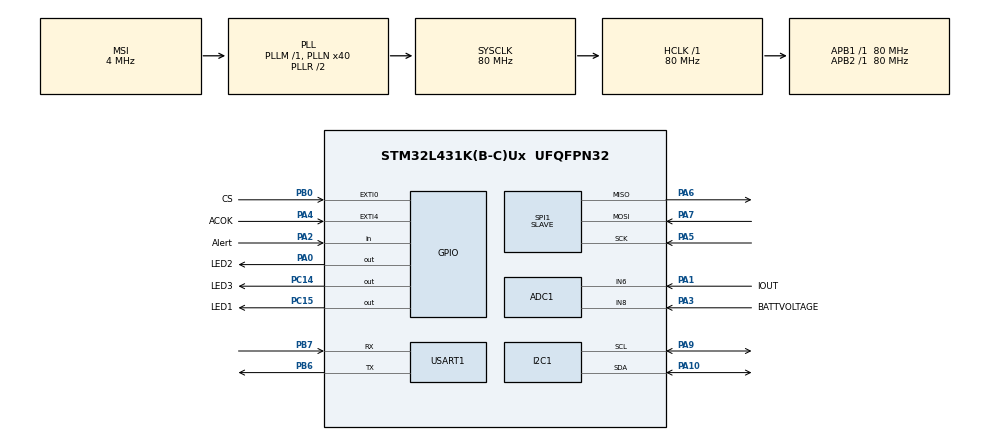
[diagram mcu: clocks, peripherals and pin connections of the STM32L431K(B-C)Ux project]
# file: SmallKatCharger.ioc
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ADC1.Channel-0\#ChannelRegularConversion=ADC_CHANNEL_6
ADC1.DMAContinuousRequests=DISABLE
ADC1.NbrOfConversionFlag=1
ADC1.OffsetNumber-0\#ChannelRegularConversion=ADC_OFFSET_NONE
ADC1.Rank-0\#ChannelRegularConversion=1
ADC1.SamplingTime-0\#ChannelRegularConversion=ADC_SAMPLETIME_2CYCLES_5
ADC1.master=1
Dma.ADC1.2.Direction=DMA_PERIPH_TO_MEMORY
Dma.ADC1.2.Instance=DMA1_Channel1
Dma.ADC1.2.MemDataAlignment=DMA_MDATAALIGN_HALFWORD
Dma.ADC1.2.MemInc=DMA_MINC_ENABLE
Dma.ADC1.2.Mode=DMA_NORMAL
Dma.ADC1.2.PeriphDataAlignment=DMA_PDATAALIGN_HALFWORD
Dma.ADC1.2.PeriphInc=DMA_PINC_DISABLE
Dma.ADC1.2.Priority=DMA_PRIORITY_LOW
Dma.Request0=SPI1_RX
Dma.Request1=SPI1_TX
Dma.Request2=ADC1
Dma.SPI1_RX.0.Direction=DMA_PERIPH_TO_MEMORY
Dma.SPI1_RX.0.Instance=DMA1_Channel2
Dma.SPI1_RX.0.MemDataAlignment=DMA_MDATAALIGN_HALFWORD
Dma.SPI1_RX.0.MemInc=DMA_MINC_ENABLE
Dma.SPI1_RX.0.Mode=DMA_NORMAL
Dma.SPI1_RX.0.PeriphDataAlignment=DMA_PDATAALIGN_HALFWORD
Dma.SPI1_RX.0.PeriphInc=DMA_PINC_DISABLE
Dma.SPI1_RX.0.Priority=DMA_PRIORITY_LOW
Dma.SPI1_TX.1.Direction=DMA_MEMORY_TO_PERIPH
Dma.SPI1_TX.1.Instance=DMA1_Channel3
Dma.SPI1_TX.1.MemDataAlignment=DMA_MDATAALIGN_HALFWORD
Dma.SPI1_TX.1.MemInc=DMA_MINC_ENABLE
Dma.SPI1_TX.1.Mode=DMA_NORMAL
Dma.SPI1_TX.1.PeriphDataAlignment=DMA_PDATAALIGN_HALFWORD
Dma.SPI1_TX.1.PeriphInc=DMA_PINC_DISABLE
Dma.SPI1_TX.1.Priority=DMA_PRIORITY_LOW
I2C1.I2C_Fall_Time=10
I2C1.I2C_Rise_Time=10
I2C1.SMBusOwnAddress=0x12
I2C1.Speed=50
I2C1.Timeout=0x000083D0
I2C1.Timing=0xC010195F
Mcu.Family=STM32L4
Mcu.Name=STM32L431K(B-C)Ux
Mcu.Package=UFQFPN32
NVIC.ADC1_IRQn=true\:0\:0\:false\:false\:true\:true
NVIC.DMA1_Channel1_IRQn=true\:0\:0\:false\:false\:true\:false
NVIC.DMA1_Channel2_IRQn=true\:0\:0\:false\:false\:true\:false
NVIC.DMA1_Channel3_IRQn=true\:0\:0\:false\:false\:true\:false
NVIC.EXTI0_IRQn=true\:0\:0\:false\:true\:true\:2\:true
NVIC.EXTI4_IRQn=true\:0\:0\:false\:true\:true\:1\:true
NVIC.I2C1_ER_IRQn=true\:0\:0\:false\:false\:true\:true
NVIC.I2C1_EV_IRQn=true\:0\:0\:false\:false\:true\:true
NVIC.PriorityGroup=NVIC_PRIORITYGROUP_4
NVIC.SPI1_IRQn=true\:0\:0\:false\:false\:true\:true
NVIC.TIM7_IRQn=true\:0\:0\:false\:false\:true\:true
NVIC.USART1_IRQn=true\:0\:0\:false\:false\:true\:true
PA0.GPIO_Label=LED2
PA0.Signal=GPIO_Output
PA1.GPIO_Label=IOUT
PA1.Signal=ADCx_IN6
PA10.Mode=SMBus-two-wire-Interface
PA10.Signal=I2C1_SDA
PA13\ (JTMS-SWDIO).Mode=Serial_Wire
PA13\ (JTMS-SWDIO).Signal=SYS_JTMS-SWDIO
PA14\ (JTCK-SWCLK).Mode=Serial_Wire
PA14\ (JTCK-SWCLK).Signal=SYS_JTCK-SWCLK
PA2.GPIO_Label=Alert
PA2.Signal=GPIO_Input
PA3.GPIO_Label=BATTVOLTAGE
PA3.Signal=ADCx_IN8
PA4.GPIO_Label=ACOK
PA4.Signal=GPXTI4
PA5.Mode=Full_Duplex_Slave
PA5.Signal=SPI1_SCK
PA6.Mode=Full_Duplex_Slave
PA6.Signal=SPI1_MISO
PA7.Mode=Full_Duplex_Slave
PA7.Signal=SPI1_MOSI
PA9.Mode=SMBus-two-wire-Interface
PA9.Signal=I2C1_SCL
PB0.GPIO_Label=CS
PB0.Signal=GPXTI0
PB6.Mode=Asynchronous
PB6.Signal=USART1_TX
PB7.Mode=Asynchronous
PB7.Signal=USART1_RX
PC14-OSC32_IN\ (PC14).GPIO_Label=LED3
PC14-OSC32_IN\ (PC14).Signal=GPIO_Output
PC15-OSC32_OUT\ (PC15).GPIO_Label=LED1
PC15-OSC32_OUT\ (PC15).Signal=GPIO_Output
ProjectManager.HeapSize=0x200
ProjectManager.StackSize=0x400
ProjectManager.TargetToolchain=SW4STM32
RCC.ADCFreq_Value=32000000
RCC.AHBFreq_Value=80000000
RCC.APB1Freq_Value=80000000
RCC.APB1TimFreq_Value=80000000
RCC.APB2Freq_Value=80000000
RCC.APB2TimFreq_Value=80000000
RCC.CortexFreq_Value=80000000
RCC.HCLKFreq_Value=80000000
RCC.HSE_VALUE=8000000
RCC.HSI48_VALUE=48000000
RCC.HSI_VALUE=16000000
RCC.LSE_VALUE=32768
RCC.MSI_VALUE=4000000
RCC.PLLN=40
RCC.PLLSAI1N=16
RCC.SYSCLKFreq_VALUE=80000000
RCC.SYSCLKSource=RCC_SYSCLKSOURCE_PLLCLK
RCC.VCOOutputFreq_Value=160000000
SH.ADCx_IN6.0=ADC1_IN6,IN6-Single-Ended
SH.ADCx_IN8.0=ADC1_IN8,IN8-Single-Ended
SPI1.DataSize=SPI_DATASIZE_16BIT
SPI1.Direction=SPI_DIRECTION_2LINES
SPI1.Mode=SPI_MODE_SLAVE
SPI1.VirtualType=VM_SLAVE
USART1.VirtualMode-Asynchronous=VM_ASYNC
VP_TIM7_VS_ClockSourceINT.Mode=Enable_Timer
board=custom

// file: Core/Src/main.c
/**
 ******************************************************************************
 * @file           : main.c
 * @brief          : Main program body
 ******************************************************************************
 ** This notice applies to any and all portions of this file
 * that are not between comment pairs USER CODE BEGIN and
 * USER CODE END. Other portions of this file, whether
 * inserted by the user or by software development tools
 * are owned by their respective copyright owners.
 *
 * COPYRIGHT(c) 2019 STMicroelectronics
 *
 * Redistribution and use in source and binary forms, with or without modification,
 * are permitted provided that the following conditions are met:
 *   1. Redistributions of source code must retain the above copyright notice,
 *      this list of conditions and the following disclaimer.
 *   2. Redistributions in binary form must reproduce the above copyright notice,
 *      this list of conditions and the following disclaimer in the documentation
 *      and/or other materials provided with the distribution.
 *   3. Neither the name of STMicroelectronics nor the names of its contributors
 *      may be used to endorse or promote products derived from this software
 *      without specific prior written permission.
 *
 * THIS SOFTWARE IS PROVIDED BY THE COPYRIGHT HOLDERS AND CONTRIBUTORS "AS IS"
 * AND ANY EXPRESS OR IMPLIED WARRANTIES, INCLUDING, BUT NOT LIMITED TO, THE
 * IMPLIED WARRANTIES OF MERCHANTABILITY AND FITNESS FOR A PARTICULAR PURPOSE ARE
 * DISCLAIMED. IN NO EVENT SHALL THE COPYRIGHT HOLDER OR CONTRIBUTORS BE LIABLE
 * FOR ANY DIRECT, INDIRECT, INCIDENTAL, SPECIAL, EXEMPLARY, OR CONSEQUENTIAL
 * DAMAGES (INCLUDING, BUT NOT LIMITED TO, PROCUREMENT OF SUBSTITUTE GOODS OR
 * SERVICES; LOSS OF USE, DATA, OR PROFITS; OR BUSINESS INTERRUPTION) HOWEVER
 * CAUSED AND ON ANY THEORY OF LIABILITY, WHETHER IN CONTRACT, STRICT LIABILITY,
 * OR TORT (INCLUDING NEGLIGENCE OR OTHERWISE) ARISING IN ANY WAY OUT OF THE USE
 * OF THIS SOFTWARE, EVEN IF ADVISED OF THE POSSIBILITY OF SUCH DAMAGE.
 *
 ******************************************************************************
 */
#include "main.h"
#include "stm32l4xx_hal.h"

#define DEVICEID 0xFF
#define CHARGEOPTION 0x12
#define CHARGECURRENT 0x14
#define MAXCHARGEVOLTAGE 0x12
#define MINSYSTEMVOLTAGE 0x3E
#define INPUTCURRENT 0x3F
#define MANUFACTURERID 0xFE

#define BQ24715ADDRESS 0b00100100

#define HIGHCURRENT 3000
#define CONSTVOLTAGE 500

ADC_HandleTypeDef hadc1;
DMA_HandleTypeDef hdma_adc1;

SMBUS_HandleTypeDef hsmbus1;

SPI_HandleTypeDef hspi1;
DMA_HandleTypeDef hdma_spi1_rx;
DMA_HandleTypeDef hdma_spi1_tx;

TIM_HandleTypeDef htim7;

UART_HandleTypeDef huart1;
ADC_ChannelConfTypeDef sConfig;

/*
uint8_t chargeOptions = 0b1110000101000100;
uint8_t chargeOptionsHigh= 0b11100001;
uint8_t chargeOptionsLow = 0b01000100;

uint8_t chargeCurrent = 0b0001100100000000;
uint8_t chargeCurrentHigh = 0b00011001;
uint8_t chargeCurrentLow = 0b00000000;

uint8_t chargeVoltage = 0b0010000011010000;
uint8_t chargeVoltageHigh = 0b00100000;
uint8_t chargeVoltageLow = 0b11010000;

uint8_t minSystemVoltage = 0b0001100000000000;
uint8_t minSystemVoltageHigh = 0b00011000;
uint8_t minSystemVoltageLow = 0b00000000;
 */
uint8_t setChargeOptions[3] = {CHARGEOPTION, 0b01000100, 0b11100001};//set charging state to default
uint8_t setChargeCurrent[3] ={CHARGECURRENT, 0b00000000, 0b00011001};//set charge current to 6.4A
uint8_t setChargeVoltage[3] = {MAXCHARGEVOLTAGE, 0b11010000, 0b00100000};//set charge voltage to ~8.4 volts
uint8_t setMinSystemVoltage[3] = {MINSYSTEMVOLTAGE, 0b00000000, 0b00011000};//set min voltage to ~6.2 volts
uint8_t setInputCurrent[3] = {INPUTCURRENT, 0b11000000, 0b00011111};//set input current to max
uint32_t ADCData[8];

void SystemClock_Config(void);
static void MX_GPIO_Init(void);
static void MX_DMA_Init(void);
static void MX_SPI1_Init(void);
static void MX_I2C1_SMBUS_Init(void);
static void MX_USART1_UART_Init(void);
static void MX_TIM7_Init(void);
static void MX_ADC1_Init(void);
static void MX_NVIC_Init(void);

int i = 0;
void initCharger(){
	uint8_t TData[1] = {DEVICEID};
	uint8_t RData[2];

	if(HAL_SMBUS_Master_Transmit_IT(&hsmbus1, BQ24715ADDRESS, setChargeVoltage, 3, SMBUS_AUTOEND_MODE) != HAL_OK){//might change back to i
		i=0;
		return;
	}
	//		Error_Handler();
	//	}
	i++;
	HAL_Delay(100);//worked at 1

	//	HAL_SMBUS_Master_Receive_IT(&hsmbus1, BQ24715ADDRESS, RData, 2, SMBUS_AUTOEND_MODE);
	//	if(RData[0] == 0&& RData[1] == 0){
	//		while(1){
	//			HAL_GPIO_TogglePin(LED1_GPIO_Port, LED1_Pin);
	//			HAL_GPIO_TogglePin(LED2_GPIO_Port, LED2_Pin);
	//			HAL_GPIO_TogglePin(LED3_GPIO_Port, LED3_Pin);
	//			HAL_Delay(100);
	//		}
	//	}
	////	else{
	//		HAL_SMBUS_Master_Transmit_IT(&hsmbus1, BQ24715ADDRESS, setChargeOptions, 3, SMBUS_AUTOEND_MODE);
	//		HAL_Delay(1);
	//		HAL_SMBUS_Master_Transmit_IT(&hsmbus1, BQ24715ADDRESS, setChargeVoltage, 3, SMBUS_AUTOEND_MODE);
	//		HAL_Delay(1);
	//		HAL_SMBUS_Master_Transmit_IT(&hsmbus1, BQ24715ADDRESS, setChargeCurrent, 3, SMBUS_AUTOEND_MODE);
	//		HAL_Delay(1);
	//		HAL_SMBUS_Master_Transmit_IT(&hsmbus1, BQ24715ADDRESS, setMinSystemVoltage, 3, SMBUS_AUTOEND_MODE);
	//		HAL_Delay(1);
	//		HAL_SMBUS_Master_Transmit_IT(&hsmbus1, BQ24715ADDRESS, setInputCurrent, 3, SMBUS_AUTOEND_MODE);
	//		HAL_Delay(1);
	//	}

}
uint16_t BattVoltage = 0;
uint16_t chargeCurrent = 0;

void readVoltage(){
	//read adc voltage divider

	sConfig.Channel = ADC_CHANNEL_8;
	sConfig.Rank = ADC_REGULAR_RANK_2;
	sConfig.SamplingTime = ADC_SAMPLETIME_2CYCLES_5;
	BattVoltage = HAL_ADC_GetValue(&hadc1);

}
void getCurrent(){
	//read adc current
	sConfig.Channel = ADC_CHANNEL_6;
	sConfig.Rank = ADC_REGULAR_RANK_2;
	sConfig.SamplingTime = ADC_SAMPLETIME_2CYCLES_5;
	chargeCurrent = HAL_ADC_GetValue(&hadc1);
}
void setCurrentState(){
	//if current is > x turn on led 1, so on
	if(chargeCurrent>HIGHCURRENT){
		LED1_GPIO_Port->ODR |= LED1_Pin;
	}
	else{
		LED1_GPIO_Port->ODR &= ~LED1_Pin;
	}
	if(chargeCurrent>CONSTVOLTAGE){
		LED2_GPIO_Port->ODR |= LED2_Pin;
	}
	else{
		LED2_GPIO_Port->ODR &= ~LED2_Pin;
	}
	if(chargeCurrent<CONSTVOLTAGE){
		LED3_GPIO_Port->ODR |= LED3_Pin;
	}
	else{
		LED3_GPIO_Port->ODR &= ~LED3_Pin;
	}

}

int main(void)
{

	/* MCU Configuration----------------------------------------------------------*/

	/* Reset of all peripherals, Initializes the Flash interface and the Systick. */
	HAL_Init();

	/* Configure the system clock */
	SystemClock_Config();

	/* Initialize all configured peripherals */
	MX_GPIO_Init();
	MX_DMA_Init();
	MX_SPI1_Init();
	MX_I2C1_SMBUS_Init();
	MX_USART1_UART_Init();
	MX_TIM7_Init();
	MX_ADC1_Init();

	/* Initialize interrupts */
	MX_NVIC_Init();
	printf(BQ24715ADDRESS);

	/* Infinite loop */
	/* USER CODE BEGIN WHILE */
	initCharger();
	initCharger();
	initCharger();
	initCharger();
	while (1)
	{
		initCharger();

		/* USER CODE END WHILE */

	}

}

void SystemClock_Config(void)
{

	RCC_OscInitTypeDef RCC_OscInitStruct;
	RCC_ClkInitTypeDef RCC_ClkInitStruct;
	RCC_PeriphCLKInitTypeDef PeriphClkInit;

	/**Initializes the CPU, AHB and APB busses clocks
	 */
	RCC_OscInitStruct.OscillatorType = RCC_OSCILLATORTYPE_MSI;
	RCC_OscInitStruct.MSIState = RCC_MSI_ON;
	RCC_OscInitStruct.MSICalibrationValue = 0;
	RCC_OscInitStruct.MSIClockRange = RCC_MSIRANGE_6;
	RCC_OscInitStruct.PLL.PLLState = RCC_PLL_ON;
	RCC_OscInitStruct.PLL.PLLSource = RCC_PLLSOURCE_MSI;
	RCC_OscInitStruct.PLL.PLLM = 1;
	RCC_OscInitStruct.PLL.PLLN = 40;
	RCC_OscInitStruct.PLL.PLLP = RCC_PLLP_DIV7;
	RCC_OscInitStruct.PLL.PLLQ = RCC_PLLQ_DIV2;
	RCC_OscInitStruct.PLL.PLLR = RCC_PLLR_DIV2;
	if (HAL_RCC_OscConfig(&RCC_OscInitStruct) != HAL_OK)
	{
		_Error_Handler(__FILE__, __LINE__);
	}

	/**Initializes the CPU, AHB and APB busses clocks
	 */
	RCC_ClkInitStruct.ClockType = RCC_CLOCKTYPE_HCLK|RCC_CLOCKTYPE_SYSCLK
			|RCC_CLOCKTYPE_PCLK1|RCC_CLOCKTYPE_PCLK2;
	RCC_ClkInitStruct.SYSCLKSource = RCC_SYSCLKSOURCE_PLLCLK;
	RCC_ClkInitStruct.AHBCLKDivider = RCC_SYSCLK_DIV1;
	RCC_ClkInitStruct.APB1CLKDivider = RCC_HCLK_DIV1;
	RCC_ClkInitStruct.APB2CLKDivider = RCC_HCLK_DIV1;

	if (HAL_RCC_ClockConfig(&RCC_ClkInitStruct, FLASH_LATENCY_4) != HAL_OK)
	{
		_Error_Handler(__FILE__, __LINE__);
	}

	PeriphClkInit.PeriphClockSelection = RCC_PERIPHCLK_USART1|RCC_PERIPHCLK_I2C1
			|RCC_PERIPHCLK_ADC;
	PeriphClkInit.Usart1ClockSelection = RCC_USART1CLKSOURCE_PCLK2;
	PeriphClkInit.I2c1ClockSelection = RCC_I2C1CLKSOURCE_PCLK1;
	PeriphClkInit.AdcClockSelection = RCC_ADCCLKSOURCE_PLLSAI1;
	PeriphClkInit.PLLSAI1.PLLSAI1Source = RCC_PLLSOURCE_MSI;
	PeriphClkInit.PLLSAI1.PLLSAI1M = 1;
	PeriphClkInit.PLLSAI1.PLLSAI1N = 16;
	PeriphClkInit.PLLSAI1.PLLSAI1P = RCC_PLLP_DIV7;
	PeriphClkInit.PLLSAI1.PLLSAI1Q = RCC_PLLQ_DIV2;
	PeriphClkInit.PLLSAI1.PLLSAI1R = RCC_PLLR_DIV2;
	PeriphClkInit.PLLSAI1.PLLSAI1ClockOut = RCC_PLLSAI1_ADC1CLK;
	if (HAL_RCCEx_PeriphCLKConfig(&PeriphClkInit) != HAL_OK)
	{
		_Error_Handler(__FILE__, __LINE__);
	}

	/**Configure the main internal regulator output voltage
	 */
	if (HAL_PWREx_ControlVoltageScaling(PWR_REGULATOR_VOLTAGE_SCALE1) != HAL_OK)
	{
		_Error_Handler(__FILE__, __LINE__);
	}

	/**Configure the Systick interrupt time
	 */
	HAL_SYSTICK_Config(HAL_RCC_GetHCLKFreq()/1000);

	/**Configure the Systick
	 */
	HAL_SYSTICK_CLKSourceConfig(SYSTICK_CLKSOURCE_HCLK);

	/* SysTick_IRQn interrupt configuration */
	HAL_NVIC_SetPriority(SysTick_IRQn, 0, 0);
}

/**
 * @brief NVIC Configuration.
 * @retval None
 */
static void MX_NVIC_Init(void)
{
	/* EXTI4_IRQn interrupt configuration */
	HAL_NVIC_SetPriority(EXTI4_IRQn, 0, 0);
	HAL_NVIC_EnableIRQ(EXTI4_IRQn);
	/* EXTI0_IRQn interrupt configuration */
	HAL_NVIC_SetPriority(EXTI0_IRQn, 0, 0);
	HAL_NVIC_EnableIRQ(EXTI0_IRQn);
}

/* ADC1 init function */
static void MX_ADC1_Init(void)
{

	ADC_ChannelConfTypeDef sConfig;

	/**Common config
	 */
	hadc1.Instance = ADC1;
	hadc1.Init.ClockPrescaler = ADC_CLOCK_ASYNC_DIV1;
	hadc1.Init.Resolution = ADC_RESOLUTION_12B;
	hadc1.Init.DataAlign = ADC_DATAALIGN_RIGHT;
	hadc1.Init.ScanConvMode = ADC_SCAN_DISABLE;
	hadc1.Init.EOCSelection = ADC_EOC_SINGLE_CONV;
	hadc1.Init.LowPowerAutoWait = DISABLE;
	hadc1.Init.ContinuousConvMode = DISABLE;
	hadc1.Init.NbrOfConversion = 1;
	hadc1.Init.DiscontinuousConvMode = DISABLE;
	hadc1.Init.ExternalTrigConv = ADC_SOFTWARE_START;
	hadc1.Init.ExternalTrigConvEdge = ADC_EXTERNALTRIGCONVEDGE_NONE;
	hadc1.Init.DMAContinuousRequests = DISABLE;
	hadc1.Init.Overrun = ADC_OVR_DATA_PRESERVED;
	hadc1.Init.OversamplingMode = DISABLE;
	if (HAL_ADC_Init(&hadc1) != HAL_OK)
	{
		_Error_Handler(__FILE__, __LINE__);
	}

	/**Configure Regular Channel
	 */
	sConfig.Channel = ADC_CHANNEL_6;
	sConfig.Rank = ADC_REGULAR_RANK_1;
	sConfig.SamplingTime = ADC_SAMPLETIME_2CYCLES_5;
	sConfig.SingleDiff = ADC_SINGLE_ENDED;
	sConfig.OffsetNumber = ADC_OFFSET_NONE;
	sConfig.Offset = 0;
	if (HAL_ADC_ConfigChannel(&hadc1, &sConfig) != HAL_OK)
	{
		_Error_Handler(__FILE__, __LINE__);
	}

}

/* I2C1 init function */
static void MX_I2C1_SMBUS_Init(void)
{

	hsmbus1.Instance = I2C1;
	hsmbus1.Init.Timing = 0xC010195F;
	hsmbus1.Init.AnalogFilter = SMBUS_ANALOGFILTER_ENABLE;
	hsmbus1.Init.OwnAddress1 = 0x12;
	hsmbus1.Init.AddressingMode = SMBUS_ADDRESSINGMODE_7BIT;
	hsmbus1.Init.DualAddressMode = SMBUS_DUALADDRESS_DISABLE;
	hsmbus1.Init.OwnAddress2 = 0;
	hsmbus1.Init.OwnAddress2Masks = SMBUS_OA2_NOMASK;
	hsmbus1.Init.GeneralCallMode = SMBUS_GENERALCALL_DISABLE;
	hsmbus1.Init.NoStretchMode = SMBUS_NOSTRETCH_DISABLE;
	hsmbus1.Init.PacketErrorCheckMode = SMBUS_PEC_DISABLE;
	hsmbus1.Init.PeripheralMode = SMBUS_PERIPHERAL_MODE_SMBUS_SLAVE;
	hsmbus1.Init.SMBusTimeout = 0x000083D0;
	if (HAL_SMBUS_Init(&hsmbus1) != HAL_OK)
	{
		_Error_Handler(__FILE__, __LINE__);
	}

}

/* SPI1 init function */
static void MX_SPI1_Init(void)
{

	/* SPI1 parameter configuration*/
	hspi1.Instance = SPI1;
	hspi1.Init.Mode = SPI_MODE_SLAVE;
	hspi1.Init.Direction = SPI_DIRECTION_2LINES;
	hspi1.Init.DataSize = SPI_DATASIZE_16BIT;
	hspi1.Init.CLKPolarity = SPI_POLARITY_LOW;
	hspi1.Init.CLKPhase = SPI_PHASE_1EDGE;
	hspi1.Init.NSS = SPI_NSS_SOFT;
	hspi1.Init.FirstBit = SPI_FIRSTBIT_MSB;
	hspi1.Init.TIMode = SPI_TIMODE_DISABLE;
	hspi1.Init.CRCCalculation = SPI_CRCCALCULATION_DISABLE;
	hspi1.Init.CRCPolynomial = 7;
	hspi1.Init.CRCLength = SPI_CRC_LENGTH_DATASIZE;
	hspi1.Init.NSSPMode = SPI_NSS_PULSE_DISABLE;
	if (HAL_SPI_Init(&hspi1) != HAL_OK)
	{
		_Error_Handler(__FILE__, __LINE__);
	}

}

/* TIM7 init function */
static void MX_TIM7_Init(void)
{

	TIM_MasterConfigTypeDef sMasterConfig;

	htim7.Instance = TIM7;
	htim7.Init.Prescaler = 0;
	htim7.Init.CounterMode = TIM_COUNTERMODE_UP;
	htim7.Init.Period = 0;
	htim7.Init.AutoReloadPreload = TIM_AUTORELOAD_PRELOAD_DISABLE;
	if (HAL_TIM_Base_Init(&htim7) != HAL_OK)
	{
		_Error_Handler(__FILE__, __LINE__);
	}

	sMasterConfig.MasterOutputTrigger = TIM_TRGO_RESET;
	sMasterConfig.MasterSlaveMode = TIM_MASTERSLAVEMODE_DISABLE;
	if (HAL_TIMEx_MasterConfigSynchronization(&htim7, &sMasterConfig) != HAL_OK)
	{
		_Error_Handler(__FILE__, __LINE__);
	}

}

/* USART1 init function */
static void MX_USART1_UART_Init(void)
{

	huart1.Instance = USART1;
	huart1.Init.BaudRate = 115200;
	huart1.Init.WordLength = UART_WORDLENGTH_8B;
	huart1.Init.StopBits = UART_STOPBITS_1;
	huart1.Init.Parity = UART_PARITY_NONE;
	huart1.Init.Mode = UART_MODE_TX_RX;
	huart1.Init.HwFlowCtl = UART_HWCONTROL_NONE;
	huart1.Init.OverSampling = UART_OVERSAMPLING_16;
	huart1.Init.OneBitSampling = UART_ONE_BIT_SAMPLE_DISABLE;
	huart1.AdvancedInit.AdvFeatureInit = UART_ADVFEATURE_NO_INIT;
	if (HAL_UART_Init(&huart1) != HAL_OK)
	{
		_Error_Handler(__FILE__, __LINE__);
	}

}

static void MX_DMA_Init(void)
{
	/* DMA controller clock enable */
	__HAL_RCC_DMA1_CLK_ENABLE();

	/* DMA interrupt init */
	/* DMA1_Channel1_IRQn interrupt configuration */
	HAL_NVIC_SetPriority(DMA1_Channel1_IRQn, 0, 0);
	HAL_NVIC_EnableIRQ(DMA1_Channel1_IRQn);
	/* DMA1_Channel2_IRQn interrupt configuration */
	HAL_NVIC_SetPriority(DMA1_Channel2_IRQn, 0, 0);
	HAL_NVIC_EnableIRQ(DMA1_Channel2_IRQn);
	/* DMA1_Channel3_IRQn interrupt configuration */
	HAL_NVIC_SetPriority(DMA1_Channel3_IRQn, 0, 0);
	HAL_NVIC_EnableIRQ(DMA1_Channel3_IRQn);

}

/** Configure pins as
 * Analog
 * Input
 * Output
 * EVENT_OUT
 * EXTI
 */
static void MX_GPIO_Init(void)
{

	GPIO_InitTypeDef GPIO_InitStruct;

	/* GPIO Ports Clock Enable */
	__HAL_RCC_GPIOC_CLK_ENABLE();
	__HAL_RCC_GPIOA_CLK_ENABLE();
	__HAL_RCC_GPIOB_CLK_ENABLE();

	/*Configure GPIO pin Output Level */
	HAL_GPIO_WritePin(GPIOC, LED3_Pin|LED1_Pin, GPIO_PIN_RESET);

	/*Configure GPIO pin Output Level */
	HAL_GPIO_WritePin(LED2_GPIO_Port, LED2_Pin, GPIO_PIN_RESET);

	/*Configure GPIO pins : LED3_Pin LED1_Pin */
	GPIO_InitStruct.Pin = LED3_Pin|LED1_Pin;
	GPIO_InitStruct.Mode = GPIO_MODE_OUTPUT_PP;
	GPIO_InitStruct.Pull = GPIO_NOPULL;
	GPIO_InitStruct.Speed = GPIO_SPEED_FREQ_LOW;
	HAL_GPIO_Init(GPIOC, &GPIO_InitStruct);

	/*Configure GPIO pin : LED2_Pin */
	GPIO_InitStruct.Pin = LED2_Pin;
	GPIO_InitStruct.Mode = GPIO_MODE_OUTPUT_PP;
	GPIO_InitStruct.Pull = GPIO_NOPULL;
	GPIO_InitStruct.Speed = GPIO_SPEED_FREQ_LOW;
	HAL_GPIO_Init(LED2_GPIO_Port, &GPIO_InitStruct);

	/*Configure GPIO pin : Alert_Pin */
	GPIO_InitStruct.Pin = Alert_Pin;
	GPIO_InitStruct.Mode = GPIO_MODE_INPUT;
	GPIO_InitStruct.Pull = GPIO_NOPULL;
	HAL_GPIO_Init(Alert_GPIO_Port, &GPIO_InitStruct);

	/*Configure GPIO pin : ACOK_Pin */
	GPIO_InitStruct.Pin = ACOK_Pin;
	GPIO_InitStruct.Mode = GPIO_MODE_IT_RISING;
	GPIO_InitStruct.Pull = GPIO_NOPULL;
	HAL_GPIO_Init(ACOK_GPIO_Port, &GPIO_InitStruct);

	/*Configure GPIO pin : CS_Pin */
	GPIO_InitStruct.Pin = CS_Pin;
	GPIO_InitStruct.Mode = GPIO_MODE_IT_RISING;
	GPIO_InitStruct.Pull = GPIO_NOPULL;
	HAL_GPIO_Init(CS_GPIO_Port, &GPIO_InitStruct);

}

void _Error_Handler(char *file, int line)
{
	while(1)
	{
	}
}

/************************ (C) COPYRIGHT STMicroelectronics *****END OF FILE****/
